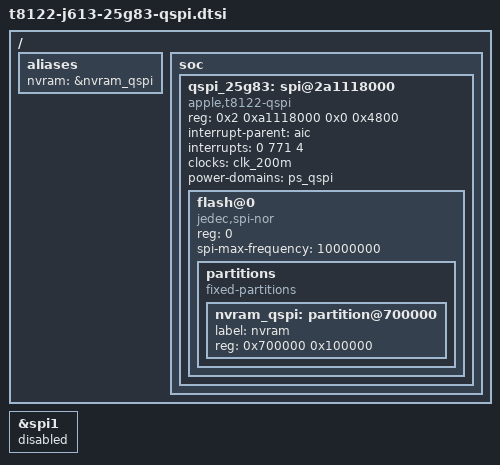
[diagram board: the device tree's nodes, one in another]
// SPDX-License-Identifier: GPL-2.0+ OR MIT
/* Opt-in J613 25G83 variant. Do not include for the working 14.8.3 SPI1 path.
 * ADT /arm-io/qspi: P=0x2a1118000 C=P+0x800 IRQ=771 gate=73.
 * Controller defaults read-only; bounded writes need explicit runtime opt-in.
 * Leave MTD openable O_RDWR
 * because asahi-bless uses O_RDWR for get_boot_volume, without issuing writes.
 */
/ {
	aliases {
		nvram = &nvram_qspi;
	};
	soc {
		qspi_25g83: spi@2a1118000 {
			compatible = "apple,t8122-qspi";
			reg = <0x2 0xa1118000 0x0 0x4800>;
			interrupt-parent = <&aic>;
			interrupts = <0 771 4>;
			clocks = <&clk_200m>;
			power-domains = <&ps_qspi>;
			#address-cells = <1>;
			#size-cells = <0>;
			status = "okay";
			flash@0 {
				compatible = "jedec,spi-nor";
				reg = <0>;
				spi-max-frequency = <10000000>;
				partitions {
					compatible = "fixed-partitions";
					#address-cells = <1>;
					#size-cells = <1>;
					nvram_qspi: partition@700000 {
						label = "nvram";
						reg = <0x700000 0x100000>;
					};
				};
			};
		};
	};
};
&spi1 { status = "disabled"; };
